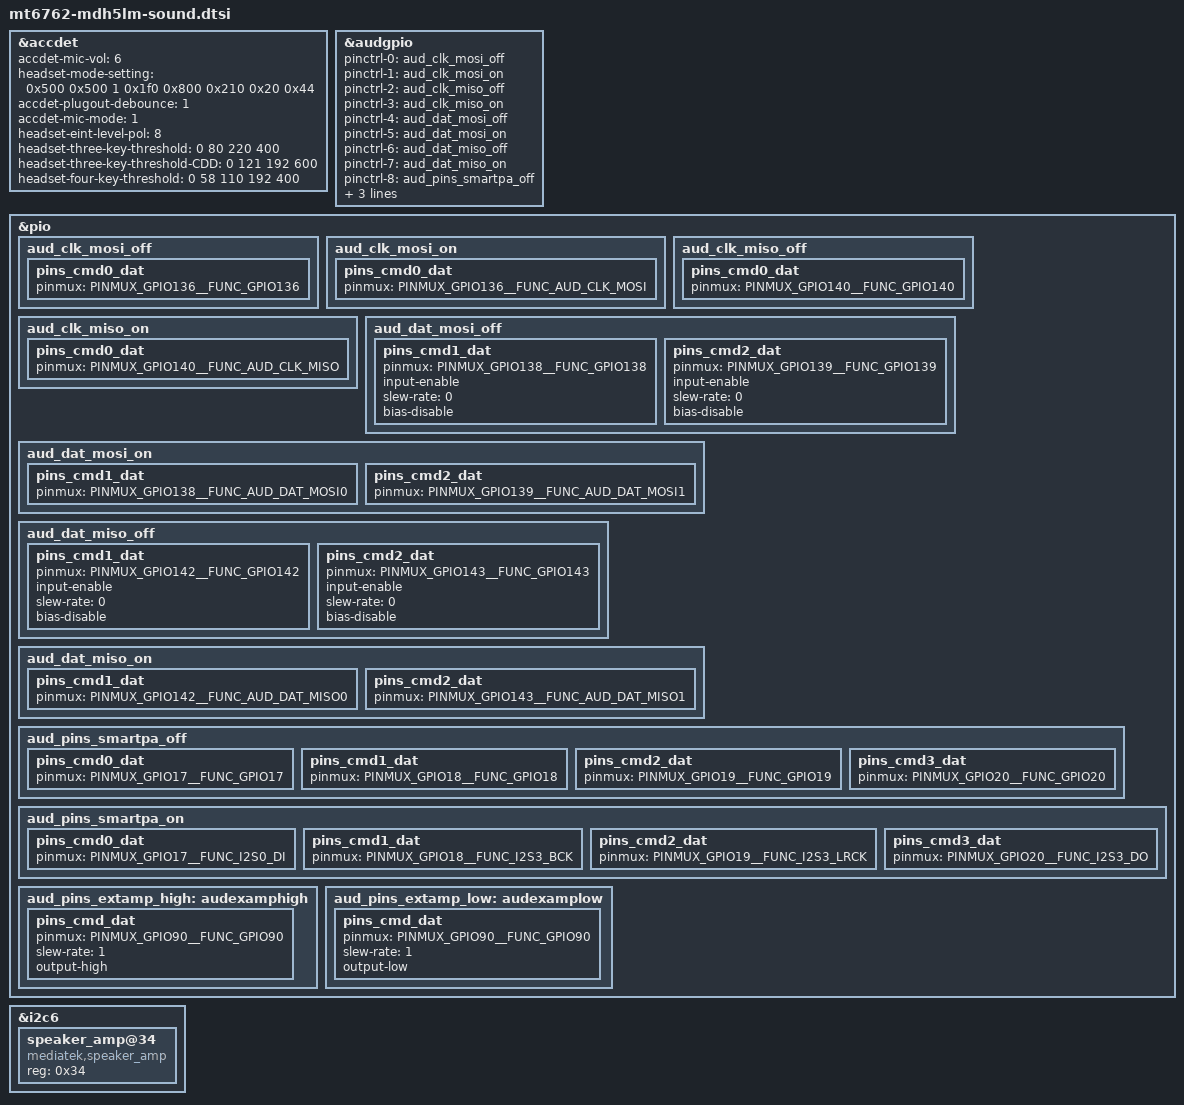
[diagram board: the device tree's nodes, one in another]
/*
 * LG Electronics MT6765 HDK sound device tree source
 *
 * Copyright (c) 2018 LG Electronics Co., Ltd.
 *              http://www.lge.com
 *
 */

/* accdet start */
&accdet {
    accdet-mic-vol = <6>;
    headset-mode-setting = <0x500 0x500 1 0x1f0 0x800 0x210 0x20 0x44>;
    accdet-plugout-debounce = <1>;
    accdet-mic-mode = <1>;
    headset-eint-level-pol = <8>;
    headset-three-key-threshold = <0 80 220 400>;
    headset-three-key-threshold-CDD = <0 121 192 600>;
    headset-four-key-threshold = <0 58 110 192 400>;
    status = "okay";
};
/* accdet end */

/* AUDIO GPIO standardization */
&audgpio {
    pinctrl-names = "aud_clk_mosi_off",
            "aud_clk_mosi_on",
            "aud_clk_miso_off",
            "aud_clk_miso_on",
            "aud_dat_mosi_off",
            "aud_dat_mosi_on",
            "aud_dat_miso_off",
            "aud_dat_miso_on",
            "aud_smartpa_off",
            "aud_smartpa_on",
            "extamp-pullhigh",
            "extamp-pulllow";
    pinctrl-0 = <&aud_clk_mosi_off>;
    pinctrl-1 = <&aud_clk_mosi_on>;
    pinctrl-2 = <&aud_clk_miso_off>;
    pinctrl-3 = <&aud_clk_miso_on>;
    pinctrl-4 = <&aud_dat_mosi_off>;
    pinctrl-5 = <&aud_dat_mosi_on>;
    pinctrl-6 = <&aud_dat_miso_off>;
    pinctrl-7 = <&aud_dat_miso_on>;
    pinctrl-8 = <&aud_pins_smartpa_off>;
    pinctrl-9 = <&aud_pins_smartpa_on>;
    pinctrl-10 = <&aud_pins_extamp_high>;
    pinctrl-11 = <&aud_pins_extamp_low>;
    status = "okay";
};

&pio {
    aud_clk_mosi_off: aud_clk_mosi_off {
        pins_cmd0_dat {
            pinmux = <PINMUX_GPIO136__FUNC_GPIO136>;
        };
    };

    aud_clk_mosi_on: aud_clk_mosi_on {
        pins_cmd0_dat {
            pinmux = <PINMUX_GPIO136__FUNC_AUD_CLK_MOSI>;
        };
    };

    aud_clk_miso_off: aud_clk_miso_off {
        pins_cmd0_dat {
            pinmux = <PINMUX_GPIO140__FUNC_GPIO140>;
        };
    };

    aud_clk_miso_on: aud_clk_miso_on {
        pins_cmd0_dat {
            pinmux = <PINMUX_GPIO140__FUNC_AUD_CLK_MISO>;
        };
    };

    aud_dat_mosi_off: aud_dat_mosi_off {
        pins_cmd1_dat {
            pinmux = <PINMUX_GPIO138__FUNC_GPIO138>;
            input-enable;
            slew-rate = <0>;
            bias-disable;
        };
        pins_cmd2_dat {
            pinmux = <PINMUX_GPIO139__FUNC_GPIO139>;
            input-enable;
            slew-rate = <0>;
            bias-disable;
        };
    };

    aud_dat_mosi_on: aud_dat_mosi_on {
        pins_cmd1_dat {
            pinmux = <PINMUX_GPIO138__FUNC_AUD_DAT_MOSI0>;
        };
        pins_cmd2_dat {
            pinmux = <PINMUX_GPIO139__FUNC_AUD_DAT_MOSI1>;
        };
    };

    aud_dat_miso_off: aud_dat_miso_off {
        pins_cmd1_dat {
            pinmux = <PINMUX_GPIO142__FUNC_GPIO142>;
            input-enable;
            slew-rate = <0>;
            bias-disable;
        };
        pins_cmd2_dat {
            pinmux = <PINMUX_GPIO143__FUNC_GPIO143>;
            input-enable;
            slew-rate = <0>;
            bias-disable;
        };
    };

    aud_dat_miso_on: aud_dat_miso_on {
        pins_cmd1_dat {
            pinmux = <PINMUX_GPIO142__FUNC_AUD_DAT_MISO0>;
        };
        pins_cmd2_dat {
            pinmux = <PINMUX_GPIO143__FUNC_AUD_DAT_MISO1>;
        };
    };

    aud_pins_smartpa_off: aud_pins_smartpa_off {
        pins_cmd0_dat {
            pinmux = <PINMUX_GPIO17__FUNC_GPIO17>;
        };
        pins_cmd1_dat {
            pinmux = <PINMUX_GPIO18__FUNC_GPIO18>;
        };
        pins_cmd2_dat {
            pinmux = <PINMUX_GPIO19__FUNC_GPIO19>;
        };
        pins_cmd3_dat {
            pinmux = <PINMUX_GPIO20__FUNC_GPIO20>;
        };
    };

    aud_pins_smartpa_on: aud_pins_smartpa_on {
        pins_cmd0_dat {
            pinmux = <PINMUX_GPIO17__FUNC_I2S0_DI>;
        };
        pins_cmd1_dat {
            pinmux = <PINMUX_GPIO18__FUNC_I2S3_BCK>;
        };
        pins_cmd2_dat {
            pinmux = <PINMUX_GPIO19__FUNC_I2S3_LRCK>;
        };
        pins_cmd3_dat {
            pinmux = <PINMUX_GPIO20__FUNC_I2S3_DO>;
        };
    };


/* audio ext amp */
	aud_pins_extamp_high: audexamphigh {
		pins_cmd_dat {
			pinmux = <PINMUX_GPIO90__FUNC_GPIO90>;
			slew-rate = <1>;
			output-high;
		};
	};

	aud_pins_extamp_low: audexamplow {
		pins_cmd_dat {
			pinmux = <PINMUX_GPIO90__FUNC_GPIO90>;
			slew-rate = <1>;
			output-low;
		};
	};

};

&i2c6 {
	speaker_amp@34 {
		compatible = "mediatek,speaker_amp";
		reg = <0x34>;
		status = "ok";
	};
};
/* AUDIO end */
